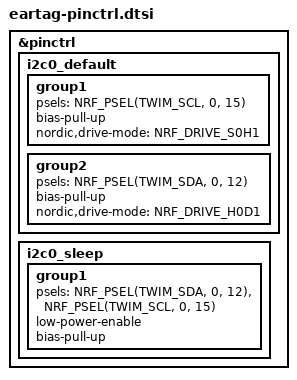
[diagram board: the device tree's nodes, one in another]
&pinctrl {
	i2c0_default: i2c0_default {
		group1 {
			psels = <NRF_PSEL(TWIM_SCL, 0, 15)>;
                        bias-pull-up;
                        nordic,drive-mode = <NRF_DRIVE_S0H1>;
            	};
	    	group2 {
			psels = <NRF_PSEL(TWIM_SDA, 0, 12)>;
                        bias-pull-up;
                        nordic,drive-mode = <NRF_DRIVE_H0D1>;
		};
	};

	i2c0_sleep: i2c0_sleep {
		group1 {
			psels = <NRF_PSEL(TWIM_SDA, 0, 12)>,
				<NRF_PSEL(TWIM_SCL, 0, 15)>;
			low-power-enable;
			bias-pull-up;
		};
	};

};
